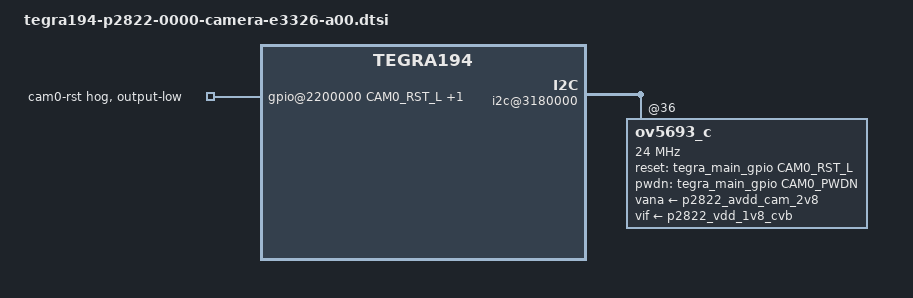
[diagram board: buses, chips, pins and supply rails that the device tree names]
/*
 * Copyright (c) 2015-2018, NVIDIA CORPORATION.  All rights reserved.
 *
 * This program is free software; you can redistribute it and/or modify
 * it under the terms of the GNU General Public License as published by
 * the Free Software Foundation; either version 2 of the License, or
 * (at your option) any later version.
 *
 * This program is distributed in the hope that it will be useful, but WITHOUT
 * ANY WARRANTY; without even the implied warranty of MERCHANTABILITY or
 * FITNESS FOR A PARTICULAR PURPOSE.  See the GNU General Public License for
 * more details.
 *
 * You should have received a copy of the GNU General Public License
 * along with this program.  If not, see <http://www.gnu.org/licenses/>.
 */
#include <t19x-common-modules/tegra194-camera-e3326-a00.dtsi>
#include "dt-bindings/clock/tegra194-clock.h"

#define CAM0_RST_L	TEGRA194_MAIN_GPIO(H, 3)
#define CAM0_PWDN	TEGRA194_MAIN_GPIO(H, 6)

/* camera control gpio definitions */

/ {
	i2c@3180000 {
		ov5693_c@36 {
			/* Define any required hw resources needed by driver */
			/* ie. clocks, io pins, power sources */
			/* mclk-index indicates the index of the */
			/* mclk-name with in the clock-names array */

			clocks = <&bpmp_clks TEGRA194_CLK_EXTPERIPH1>,
					 <&bpmp_clks TEGRA194_CLK_PLLP_OUT0>;
			clock-names = "extperiph1", "pllp_grtba";
			mclk = "extperiph1";
			clock-frequency = <24000000>;
			reset-gpios = <&tegra_main_gpio CAM0_RST_L GPIO_ACTIVE_HIGH>;
			pwdn-gpios = <&tegra_main_gpio CAM0_PWDN GPIO_ACTIVE_HIGH>;
			vana-supply = <&p2822_avdd_cam_2v8>;
			vif-supply = <&p2822_vdd_1v8_cvb>;
		};
	};

	gpio@2200000 {
		camera-control-output-low {
			gpio-hog;
			output-low;
			gpios = <CAM0_RST_L 0 CAM0_PWDN 0>;
			label = "cam0-rst", "cam0-pwdn";
		};
	};
};
